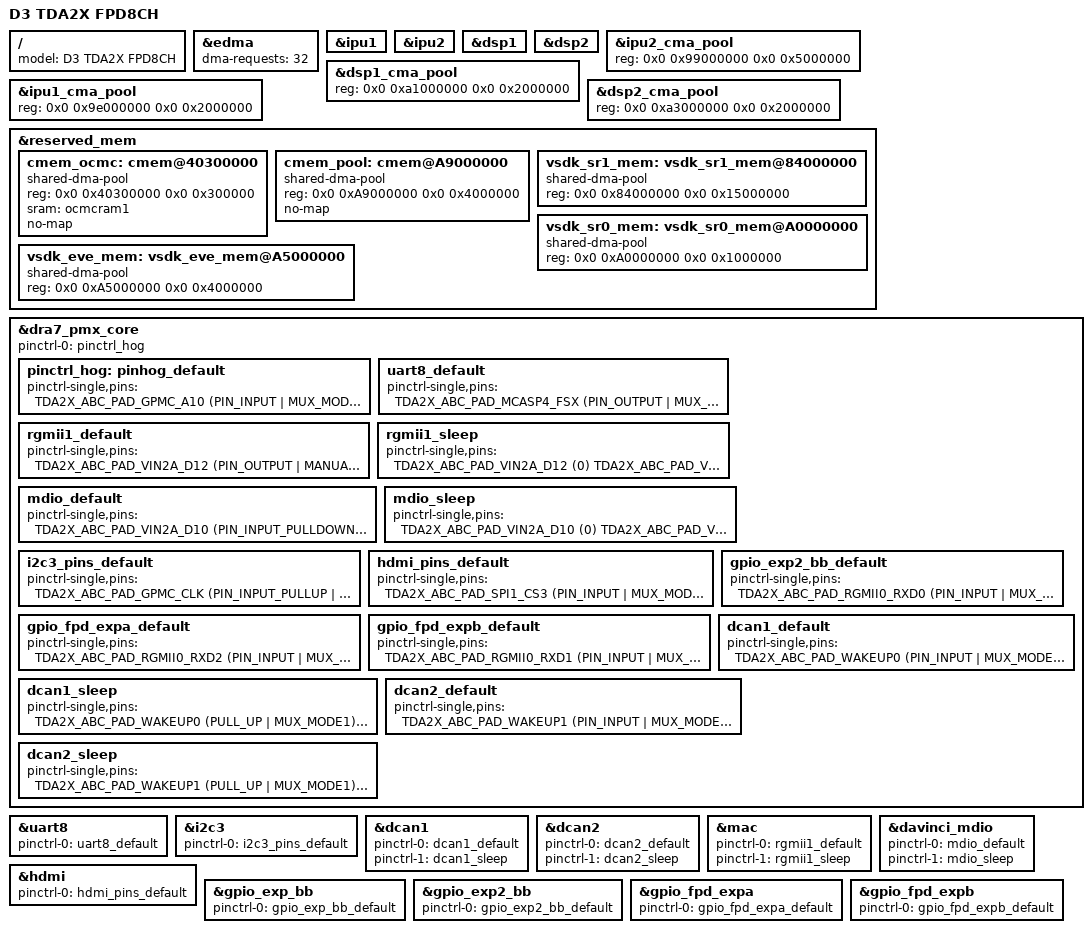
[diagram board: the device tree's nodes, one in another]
/*
 * Copyright (C) 2016 D3 Engineering
 *
 * Based on am571x-idk.dts
 * Copyright (C) 2015 Texas Instruments Incorporated
 *
 * This program is free software; you can redistribute it and/or modify
 * it under the terms of the GNU General Public License version 2 as
 * published by the Free Software Foundation.
 */
/dts-v1/;

#include "d3-tda2xx-tda2x.dtsi"
#include "d3-fpd8ch-baseboard.dtsi"
#include <dt-bindings/gpio/gpio.h>
#include <dt-bindings/interrupt-controller/irq.h>
#include <dt-bindings/net/ti-dp83867.h>

#define DISABLE_PRCM(label) &label { ti,no-idle; ti,no-reset-on-init; }
#define DISABLE_COMPLETE(label) &label { status = "disabled"; ti,no-idle; ti,no-reset-on-init; }
#define LATE_ATTACH(label) &label { ti,late-attach; ti,no-idle; ti,no-reset-on-init; }

/ {
	model = "D3 TDA2X FPD8CH";
};

/* modules used by BIOS, disable from Linux */
DISABLE_COMPLETE(vip1);
DISABLE_COMPLETE(vip2);
DISABLE_COMPLETE(vip3);
DISABLE_COMPLETE(i2c4);
DISABLE_COMPLETE(i2c5);
DISABLE_COMPLETE(wdt2);
DISABLE_COMPLETE(vpe);
DISABLE_COMPLETE(ocmcram1);
DISABLE_COMPLETE(hdmi);
DISABLE_COMPLETE(hdmi0);

/* modules shared between BIOS and Linux, Do not reset or cutoff clks */
DISABLE_PRCM(gpio1);
DISABLE_PRCM(gpio2);
DISABLE_PRCM(gpio3);
DISABLE_PRCM(gpio4);
DISABLE_PRCM(gpio5);
DISABLE_PRCM(gpio6);

/* Linux uses first 32 channels, BIOS uses last 32 */
&edma {
	dma-requests = <32>;
};

&ipu1 {
	/delete-property/ watchdog-timers;
};

&ipu2 {
	/delete-property/ watchdog-timers;
};

&dsp1 {
	/delete-property/ watchdog-timers;
};

&dsp2 {
	/delete-property/ watchdog-timers;
};

/* Update the CMA regions for Vision SDK binaries */
&ipu2_cma_pool {
	reg = <0x0 0x99000000 0x0 0x5000000>;
};

&dsp1_cma_pool {
	reg = <0x0 0xa1000000 0x0 0x2000000>;
};

&ipu1_cma_pool {
	reg = <0x0 0x9e000000 0x0 0x2000000>;
};

&dsp2_cma_pool {
	reg = <0x0 0xa3000000 0x0 0x2000000>;
};

/* Additional memory regions required for Vision SDK
 * Keep this in sync with VSDK apps/build/tda2xx/mem_segment_definition_linux.xs
 */
&reserved_mem {
	cmem_ocmc: cmem@40300000 {
		compatible = "shared-dma-pool";
		reg = <0x0 0x40300000 0x0 0x300000>;
		sram = <&ocmcram1>;
		no-map;
		status = "okay";
	};

	cmem_pool: cmem@A9000000 {
		compatible = "shared-dma-pool";
		reg = <0x0 0xA9000000 0x0 0x4000000>;
		no-map;
		status = "okay";
	};

	vsdk_sr1_mem: vsdk_sr1_mem@84000000 {
		compatible = "shared-dma-pool";
		reg = <0x0 0x84000000 0x0 0x15000000>;
		status = "okay";
	};

	vsdk_sr0_mem: vsdk_sr0_mem@A0000000 {
		compatible = "shared-dma-pool";
		reg = <0x0 0xA0000000 0x0 0x1000000>;
		status = "okay";
	};

	vsdk_eve_mem: vsdk_eve_mem@A5000000 {
		compatible = "shared-dma-pool";
		reg = <0x0 0xA5000000 0x0 0x4000000>;
		status = "okay";
	};
};

&dra7_pmx_core {
	pinctrl-names = "default";
	pinctrl-0 = <&pinctrl_hog>;

	pinctrl_hog: pinhog_default {
		pinctrl-single,pins = <
			TDA2X_ABC_PAD_GPMC_A10	(PIN_INPUT | MUX_MODE14) /* gpmc_a10.gpio2_0 */

			/* Isolated IO */
			TDA2X_ABC_PAD_GPMC_OEN_REN (PIN_INPUT | MUX_MODE14) /* gpmc_oen_ren.gpio2_24 */
			TDA2X_ABC_PAD_GPMC_WEN (PIN_INPUT | MUX_MODE14) /* gpmc_wen.gpio2_25 */
			TDA2X_ABC_PAD_GPMC_WAIT0 (PIN_OUTPUT | MUX_MODE14) /* gpmc_wait10.gpio2_28 */
			TDA2X_ABC_PAD_GPMC_CS0 (PIN_OUTPUT | MUX_MODE14) /* gpmc_cs0.gpio2_19 */

#if 0
			/* VIN1A pinmux */
			TDA2X_ABC_PAD_VIN1A_HSYNC0  (PIN_INPUT | MUX_MODE0) /* vin1a_hsync0.vin1a_hsync0 */
			TDA2X_ABC_PAD_VIN1A_VSYNC0  (PIN_INPUT | MUX_MODE0) /* vin1a_vsync0.vin1a_vsync0 */
			TDA2X_ABC_PAD_VIN1A_CLK0  (PIN_INPUT | MUX_MODE0) /* vin1a_clk0.vin1a_clk0 */
			TDA2X_ABC_PAD_VIN1A_D0  (PIN_INPUT | MUX_MODE0) /* vin1a_d0.vin1a_d0 */
			TDA2X_ABC_PAD_VIN1A_D1  (PIN_INPUT | MUX_MODE0) /* vin1a_d1.vin1a_d1 */
			TDA2X_ABC_PAD_VIN1A_D2  (PIN_INPUT | MUX_MODE0) /* vin1a_d2.vin1a_d2 */
			TDA2X_ABC_PAD_VIN1A_D3  (PIN_INPUT | MUX_MODE0) /* vin1a_d3.vin1a_d3 */
			TDA2X_ABC_PAD_VIN1A_D4  (PIN_INPUT | MUX_MODE0) /* vin1a_d4.vin1a_d4 */
			TDA2X_ABC_PAD_VIN1A_D5  (PIN_INPUT | MUX_MODE0) /* vin1a_d5.vin1a_d5 */
			TDA2X_ABC_PAD_VIN1A_D6  (PIN_INPUT | MUX_MODE0) /* vin1a_d6.vin1a_d6 */
			TDA2X_ABC_PAD_VIN1A_D7  (PIN_INPUT | MUX_MODE0) /* vin1a_d7.vin1a_d7 */
			TDA2X_ABC_PAD_VIN1A_D8  (PIN_INPUT | MUX_MODE0) /* vin1a_d8.vin1a_d8 */
			TDA2X_ABC_PAD_VIN1A_D9  (PIN_INPUT | MUX_MODE0) /* vin1a_d9.vin1a_d9 */
			TDA2X_ABC_PAD_VIN1A_D10  (PIN_INPUT | MUX_MODE0) /* vin1a_d10.vin1a_d10 */
			TDA2X_ABC_PAD_VIN1A_D11  (PIN_INPUT | MUX_MODE0) /* vin1a_d11.vin1a_d11 */

			/* VIN1B pinmux */
			TDA2X_ABC_PAD_VIN1A_DE0  (PIN_INPUT | MUX_MODE1) /* vin1a_de0.vin1b_hsync1 */
			TDA2X_ABC_PAD_VIN1A_FLD0  (PIN_INPUT | MUX_MODE1) /* vin1a_fld0.vin1b_vsync1 */
			TDA2X_ABC_PAD_VIN1B_CLK1 (PIN_INPUT | MUX_MODE0) /* vin1b_clk1.vin1b_clk1 */
			TDA2X_ABC_PAD_VIN1A_D23  (PIN_INPUT | MUX_MODE1) /* vin1a_d23.vin1b_d0 */
			TDA2X_ABC_PAD_VIN1A_D22  (PIN_INPUT | MUX_MODE1) /* vin1a_d22.vin1b_d1 */
			TDA2X_ABC_PAD_VIN1A_D21  (PIN_INPUT | MUX_MODE1) /* vin1a_d21.vin1b_d2 */
			TDA2X_ABC_PAD_VIN1A_D20  (PIN_INPUT | MUX_MODE1) /* vin1a_d20.vin1b_d3 */
			TDA2X_ABC_PAD_VIN1A_D19  (PIN_INPUT | MUX_MODE1) /* vin1a_d19.vin1b_d4 */
			TDA2X_ABC_PAD_VIN1A_D18  (PIN_INPUT | MUX_MODE1) /* vin1a_d18.vin1b_d5 */
			TDA2X_ABC_PAD_VIN1A_D17  (PIN_INPUT | MUX_MODE1) /* vin1a_d17.vin1b_d6 */
			TDA2X_ABC_PAD_VIN1A_D16  (PIN_INPUT | MUX_MODE1) /* vin1a_d16.vin1b_d7 */

			/* VIN2A pinmux */
			TDA2X_ABC_PAD_VIN2A_HSYNC0  (PIN_INPUT | MUX_MODE0) /* vin2a_hsync0.vin2a_hsync0 */
			TDA2X_ABC_PAD_VIN2A_VSYNC0  (PIN_INPUT | MUX_MODE0) /* vin2a_vsync0.vin2a_vsync0 */
			TDA2X_ABC_PAD_VIN2A_CLK0  (PIN_INPUT | MUX_MODE0) /* vin2a_clk0.vin2a_clk0 */
			TDA2X_ABC_PAD_VIN2A_D0  (PIN_INPUT | MUX_MODE0) /* vin2a_d0.vin2a_d0 */
			TDA2X_ABC_PAD_VIN2A_D1  (PIN_INPUT | MUX_MODE0) /* vin2a_d1.vin2a_d1 */
			TDA2X_ABC_PAD_VIN2A_D2  (PIN_INPUT | MUX_MODE0) /* vin2a_d2.vin2a_d2 */
			TDA2X_ABC_PAD_VIN2A_D3  (PIN_INPUT | MUX_MODE0) /* vin2a_d3.vin2a_d3 */
			TDA2X_ABC_PAD_VIN2A_D4  (PIN_INPUT | MUX_MODE0) /* vin2a_d4.vin2a_d4 */
			TDA2X_ABC_PAD_VIN2A_D5  (PIN_INPUT | MUX_MODE0) /* vin2a_d5.vin2a_d5 */
			TDA2X_ABC_PAD_VIN2A_D6  (PIN_INPUT | MUX_MODE0) /* vin2a_d6.vin2a_d6 */
			TDA2X_ABC_PAD_VIN2A_D7  (PIN_INPUT | MUX_MODE0) /* vin2a_d7.vin2a_d7 */
			TDA2X_ABC_PAD_VIN2A_D8  (PIN_INPUT | MUX_MODE0) /* vin2a_d8.vin2a_d8 */
			TDA2X_ABC_PAD_VIN2A_D9  (PIN_INPUT | MUX_MODE0) /* vin2a_d9.vin2a_d9 */

			/* VIN3A pinmux */
			TDA2X_ABC_PAD_GPMC_A8    (PIN_INPUT | MUX_MODE2) /* gpmc_cs3.vin3a_hsync0 */
			TDA2X_ABC_PAD_GPMC_A9    (PIN_INPUT | MUX_MODE2) /* gpmc_cs3.vin3a_vsync0 */
			TDA2X_ABC_PAD_GPMC_CS3   (PIN_INPUT | MUX_MODE2) /* gpmc_cs3.vin3a_clk0 */
			TDA2X_ABC_PAD_GPMC_AD0   (PIN_INPUT | MUX_MODE2) /* gpmc_ad0.vin3a_d0 */
			TDA2X_ABC_PAD_GPMC_AD1   (PIN_INPUT | MUX_MODE2) /* gpmc_ad1.vin3a_d1 */
			TDA2X_ABC_PAD_GPMC_AD2   (PIN_INPUT | MUX_MODE2) /* gpmc_ad2.vin3a_d2 */
			TDA2X_ABC_PAD_GPMC_AD3   (PIN_INPUT | MUX_MODE2) /* gpmc_ad3.vin3a_d3 */
			TDA2X_ABC_PAD_GPMC_AD4   (PIN_INPUT | MUX_MODE2) /* gpmc_ad4.vin3a_d4 */
			TDA2X_ABC_PAD_GPMC_AD5   (PIN_INPUT | MUX_MODE2) /* gpmc_ad5.vin3a_d5 */
			TDA2X_ABC_PAD_GPMC_AD6   (PIN_INPUT | MUX_MODE2) /* gpmc_ad6.vin3a_d6 */
			TDA2X_ABC_PAD_GPMC_AD7   (PIN_INPUT | MUX_MODE2) /* gpmc_ad7.vin3a_d7 */
			TDA2X_ABC_PAD_GPMC_AD8   (PIN_INPUT | MUX_MODE2) /* gpmc_ad8.vin3a_d8 */
			TDA2X_ABC_PAD_GPMC_AD9   (PIN_INPUT | MUX_MODE2) /* gpmc_ad9.vin3a_d9 */
			TDA2X_ABC_PAD_GPMC_AD10  (PIN_INPUT | MUX_MODE2) /* gpmc_ad10.vin3a_d10 */
			TDA2X_ABC_PAD_GPMC_AD11  (PIN_INPUT | MUX_MODE2) /* gpmc_ad11.vin3a_d11 */

			/* VIN4A pinmux*/
			TDA2X_ABC_PAD_GPIO6_14  (PIN_INPUT | MUX_MODE8) /* gpio6_14.vin4a_hsync0 */
			TDA2X_ABC_PAD_GPIO6_15  (PIN_INPUT | MUX_MODE8) /* gpio6_15.vin4a_vsync0 */
			TDA2X_ABC_PAD_XREF_CLK2  (PIN_INPUT | MUX_MODE8) /* xref_clk2.vin4a_clk0 */
			TDA2X_ABC_PAD_MCASP1_ACLKR  (PIN_INPUT | MUX_MODE8) /* mcasp1_aclkr.vin4a_d0 */
			TDA2X_ABC_PAD_MCASP1_FSR  (PIN_INPUT | MUX_MODE8) /* mcasp1_fsr.vin4a_d1 */
			TDA2X_ABC_PAD_MCASP1_AXR2  (PIN_INPUT | MUX_MODE8) /* mcasp1_axr2.vin4a_d2 */
			TDA2X_ABC_PAD_MCASP1_AXR3  (PIN_INPUT | MUX_MODE8) /* mcasp1_axr3.vin4a_d3 */
			TDA2X_ABC_PAD_MCASP1_AXR4  (PIN_INPUT | MUX_MODE8) /* mcasp1_axr4.vin4a_d4 */
			TDA2X_ABC_PAD_MCASP1_AXR5  (PIN_INPUT | MUX_MODE8) /* mcasp1_axr5.vin4a_d5 */
			TDA2X_ABC_PAD_MCASP1_AXR6  (PIN_INPUT | MUX_MODE8) /* mcasp1_axr6.vin4a_d6 */
			TDA2X_ABC_PAD_MCASP1_AXR7  (PIN_INPUT | MUX_MODE8) /* mcasp1_axr7.vin4a_d7 */
			TDA2X_ABC_PAD_MCASP2_ACLKR  (PIN_INPUT | MUX_MODE8) /* mcasp2_aclkr.vin4a_d8 */
			TDA2X_ABC_PAD_MCASP2_FSR  (PIN_INPUT | MUX_MODE8) /* mcasp2_fsr.vin4a_d9 */
			TDA2X_ABC_PAD_MCASP2_AXR0  (PIN_INPUT | MUX_MODE8) /* mcasp2_axr0.vin4a_d10 */
			TDA2X_ABC_PAD_MCASP2_AXR1  (PIN_INPUT | MUX_MODE8) /* mcasp2_fsr.vin4a_d11 */

			/* VIN4B pinmux */
			TDA2X_ABC_PAD_RGMII0_TXD2  (PIN_INPUT | MUX_MODE5) /* rgmii0_txd2.vin4b_hsync1 */
			TDA2X_ABC_PAD_RGMII0_TXD1  (PIN_INPUT | MUX_MODE5) /* rgmii0_txd1.vin4b_vsync1 */
			TDA2X_ABC_PAD_MDIO_MCLK  (PIN_INPUT | MUX_MODE5) /* mdio_mclk.vin4b_clk1 */
			TDA2X_ABC_PAD_MDIO_D  (PIN_INPUT | MUX_MODE5) /* mdio_d.vin4b_d0 */
			TDA2X_ABC_PAD_UART3_RXD  (PIN_INPUT | MUX_MODE5) /* uart3_rxd.vin4b_d1 */
			TDA2X_ABC_PAD_UART3_TXD  (PIN_INPUT | MUX_MODE5) /* uart3_rxd.vin4b_d2 */
			TDA2X_ABC_PAD_RGMII0_TXC  (PIN_INPUT | MUX_MODE5) /* rgmii0_txc.vin4b_d3 */
			TDA2X_ABC_PAD_RGMII0_TXCTL  (PIN_INPUT | MUX_MODE5) /* rgmii0_txctl.vin4b_d4 */
			TDA2X_ABC_PAD_RGMII0_RXC  (PIN_INPUT | MUX_MODE5) /* rgmii0_rxc.vin4b_d5 */
			TDA2X_ABC_PAD_RGMII0_RXCTL  (PIN_INPUT | MUX_MODE5) /* rgmii0_rxctl.vin4b_d6 */
			TDA2X_ABC_PAD_RGMII0_RXD3  (PIN_INPUT | MUX_MODE5) /* rgmii0_rxd3.vin4b_d7 */

			/* VIN5A pinmux */
			TDA2X_ABC_PAD_MMC3_DAT6  (PIN_INPUT | MUX_MODE9) /* mmc3_dat6.vin5a_hsync0 */
			TDA2X_ABC_PAD_MMC3_DAT7  (PIN_INPUT | MUX_MODE9) /* mmc3_dat7.vin5a_vsync0 */
			TDA2X_ABC_PAD_GPIO6_10  (PIN_INPUT | MUX_MODE9) /* gpio6_10.vin5a_clk0 */
			TDA2X_ABC_PAD_GPIO6_11  (PIN_INPUT | MUX_MODE9) /* gpio6_11.vin5a_de0 */
			TDA2X_ABC_PAD_MCASP3_AXR1  (PIN_INPUT | MUX_MODE9) /* mcasp3_axr1.vin5a_fld0 */
			TDA2X_ABC_PAD_MMC3_DAT5  (PIN_INPUT | MUX_MODE9) /* mmc3_dat5.vin5a_d0 */
			TDA2X_ABC_PAD_MMC3_DAT4  (PIN_INPUT | MUX_MODE9) /* mmc3_dat4.vin5a_d1 */
			TDA2X_ABC_PAD_MMC3_DAT3  (PIN_INPUT | MUX_MODE9) /* mmc3_dat3.vin5a_d2 */
			TDA2X_ABC_PAD_MMC3_DAT2  (PIN_INPUT | MUX_MODE9) /* mmc3_dat2.vin5a_d3 */
			TDA2X_ABC_PAD_MMC3_DAT1  (PIN_INPUT | MUX_MODE9) /* mmc3_dat1.vin5a_d4 */
			TDA2X_ABC_PAD_MMC3_DAT0  (PIN_INPUT | MUX_MODE9) /* mmc3_dat0.vin5a_d5 */
			TDA2X_ABC_PAD_MMC3_CMD  (PIN_INPUT | MUX_MODE9) /* mmc3_dat5.vin5a_d6 */
			TDA2X_ABC_PAD_MMC3_CLK  (PIN_INPUT | MUX_MODE9) /* mmc3_dat5.vin5a_d7 */
			TDA2X_ABC_PAD_MCASP5_AXR1  (PIN_INPUT | MUX_MODE9) /* mcasp5_axr1.vin5a_d8 */
			TDA2X_ABC_PAD_MCASP5_AXR0  (PIN_INPUT | MUX_MODE9) /* mcasp5_axr0.vin5a_d9 */
			TDA2X_ABC_PAD_MCASP5_FSX  (PIN_INPUT | MUX_MODE9) /* mcasp5_fsx.vin5a_d10 */
			TDA2X_ABC_PAD_MCASP5_ACLKX  (PIN_INPUT | MUX_MODE9) /* mcasp5_aclkx.vin5a_d11 */

			/* VIN6A pinmux */
			TDA2X_ABC_PAD_MCASP1_AXR1  (PIN_INPUT | MUX_MODE7) /* mcasp1_axr1.vin6a_hsync0 */
			TDA2X_ABC_PAD_MCASP1_AXR0  (PIN_INPUT | MUX_MODE7) /* mcasp1_axr0.vin6a_vsync0 */
			TDA2X_ABC_PAD_XREF_CLK1  (PIN_INPUT | MUX_MODE7) /* xref_clk1.vin6a_clk0 */
			TDA2X_ABC_PAD_XREF_CLK0  (PIN_INPUT | MUX_MODE7) /* xref_clk0.vin6a_d0 */
			TDA2X_ABC_PAD_MCASP3_AXR0  (PIN_INPUT | MUX_MODE7) /* mcasp3_axr0.vin6a_d1 */
			TDA2X_ABC_PAD_MCASP3_FSX  (PIN_INPUT | MUX_MODE7) /* mcasp3_fsx.vin6a_d2 */
			TDA2X_ABC_PAD_MCASP3_ACLKX  (PIN_INPUT | MUX_MODE7) /* mcasp3_aclkx.vin6a_d3 */
			TDA2X_ABC_PAD_MCASP2_AXR3  (PIN_INPUT | MUX_MODE7) /* mcasp3_axr3.vin6a_d4 */
			TDA2X_ABC_PAD_MCASP2_AXR2  (PIN_INPUT | MUX_MODE7) /* mcasp3_axr2.vin6a_d5 */
			TDA2X_ABC_PAD_MCASP2_FSX  (PIN_INPUT | MUX_MODE7) /* mcasp2_fsx.vin6a_d6 */
			TDA2X_ABC_PAD_MCASP2_ACLKX  (PIN_INPUT | MUX_MODE7) /* mcasp2_aclkx.vin6a_d7 */
			TDA2X_ABC_PAD_MCASP1_AXR15  (PIN_INPUT | MUX_MODE7) /* mcasp1_axr15.vin6a_d8 */
			TDA2X_ABC_PAD_MCASP1_AXR14  (PIN_INPUT | MUX_MODE7) /* mcasp1_axr14.vin6a_d9 */
			TDA2X_ABC_PAD_MCASP1_AXR13  (PIN_INPUT | MUX_MODE7) /* mcasp1_axr13.vin6a_d10 */

			/*TDA2X_ABC_PAD_MCASP1_AXR12  (PIN_INPUT | MUX_MODE7) *//* mcasp1_axr12.vin6a_d11 */
#endif

			/*Ultrasonic*/
			TDA2X_ABC_PAD_GPMC_BEN0 (PIN_OUTPUT | MUX_MODE14) /* gpmc_ben0.gpio2_26 */
			TDA2X_ABC_PAD_MCASP1_AXR12 (PIN_OUTPUT | MUX_MODE14) /* mcasp1_axr12.gpio4_18 */
			TDA2X_ABC_PAD_GPMC_A11 (PIN_OUTPUT | MUX_MODE14) /* gpmc_a11.gpio2_1 */
			TDA2X_ABC_PAD_GPMC_BEN1 (PIN_OUTPUT | MUX_MODE14) /* gpmc_ben1.gpio2_27 */
			TDA2X_ABC_PAD_SPI1_D1 (PIN_OUTPUT | MUX_MODE14) /* spi2_d1.gpio7_8 */
			TDA2X_ABC_PAD_SPI1_D0 (PIN_OUTPUT | MUX_MODE14) /* spi1_d0.gpio7_9 */
			TDA2X_ABC_PAD_SPI1_CS1 (PIN_OUTPUT | MUX_MODE14) /* spi1_cs1.gpio7_11 */
			TDA2X_ABC_PAD_SPI1_CS0 (PIN_OUTPUT | MUX_MODE14) /* spi1_cs0.gpio7_10 */
			TDA2X_ABC_PAD_SPI1_SCLK (PIN_OUTPUT | MUX_MODE14) /* spi1_sclk.gpio7_7 */
		>;
	};

	uart8_default: uart8_default {
		pinctrl-single,pins = <
			TDA2X_ABC_PAD_MCASP4_FSX (PIN_OUTPUT | MUX_MODE3) /* mcasp4_fsx.uart8_txd */
			TDA2X_ABC_PAD_MCASP4_ACLKX (PIN_INPUT | MUX_MODE3) /* mcasp4_aclkx.uart8_rxd */
		>;
	};

	rgmii1_default: rgmii1_default {
		pinctrl-single,pins = <
			TDA2X_ABC_PAD_VIN2A_D12	(PIN_OUTPUT | MANUAL_MODE | MUX_MODE3) /* vin2a_d12.rgmii1_txc */
			TDA2X_ABC_PAD_VIN2A_D13	(PIN_OUTPUT | MANUAL_MODE | MUX_MODE3) /* vin2a_d13.rgmii1_txctl */
			TDA2X_ABC_PAD_VIN2A_D14	(PIN_OUTPUT | MANUAL_MODE | MUX_MODE3) /* vin2a_d14.rgmii1_txd3 */
			TDA2X_ABC_PAD_VIN2A_D15	(PIN_OUTPUT | MANUAL_MODE | MUX_MODE3) /* vin2a_d15.rgmii1_txd2 */
			TDA2X_ABC_PAD_VIN2A_D16	(PIN_OUTPUT | MANUAL_MODE | MUX_MODE3) /* vin2a_d16.rgmii1_txd1 */
			TDA2X_ABC_PAD_VIN2A_D17	(PIN_OUTPUT | MANUAL_MODE | MUX_MODE3) /* vin2a_d17.rgmii1_txd0 */
			TDA2X_ABC_PAD_VIN2A_D18	(PIN_INPUT_PULLDOWN | MANUAL_MODE | MUX_MODE3) /* vin2a_d18.rgmii1_rxc */
			TDA2X_ABC_PAD_VIN2A_D19	(PIN_INPUT_PULLDOWN | MANUAL_MODE | MUX_MODE3) /* vin2a_d19.rgmii1_rxctl */
			TDA2X_ABC_PAD_VIN2A_D20	(PIN_INPUT_PULLDOWN | MANUAL_MODE | MUX_MODE3) /* vin2a_d20.rgmii1_rxd3 */
			TDA2X_ABC_PAD_VIN2A_D21	(PIN_INPUT_PULLDOWN | MANUAL_MODE | MUX_MODE3) /* vin2a_d21.rgmii1_rxd2 */
			TDA2X_ABC_PAD_VIN2A_D22	(PIN_INPUT_PULLDOWN | MANUAL_MODE | MUX_MODE3) /* vin2a_d22.rgmii1_rxd1 */
			TDA2X_ABC_PAD_VIN2A_D23	(PIN_INPUT_PULLDOWN | MANUAL_MODE | MUX_MODE3) /* vin2a_d23.rgmii1_rxd0 */
		>;

	};

	rgmii1_sleep: rgmii1_sleep {
		pinctrl-single,pins = <
			TDA2X_ABC_PAD_VIN2A_D12	(0) /* vin2a_d12.rgmii1_txc */
			TDA2X_ABC_PAD_VIN2A_D13	(0) /* vin2a_d13.rgmii1_txctl */
			TDA2X_ABC_PAD_VIN2A_D14	(0) /* vin2a_d14.rgmii1_txd3 */
			TDA2X_ABC_PAD_VIN2A_D15	(0) /* vin2a_d15.rgmii1_txd2 */
			TDA2X_ABC_PAD_VIN2A_D16	(0) /* vin2a_d16.rgmii1_txd1 */
			TDA2X_ABC_PAD_VIN2A_D17	(0) /* vin2a_d17.rgmii1_txd0 */
			TDA2X_ABC_PAD_VIN2A_D18	(0) /* vin2a_d18.rgmii1_rxc */
			TDA2X_ABC_PAD_VIN2A_D19	(0) /* vin2a_d19.rgmii1_rxctl */
			TDA2X_ABC_PAD_VIN2A_D20	(0) /* vin2a_d20.rgmii1_rxd3 */
			TDA2X_ABC_PAD_VIN2A_D21	(0) /* vin2a_d21.rgmii1_rxd2 */
			TDA2X_ABC_PAD_VIN2A_D22	(0) /* vin2a_d22.rgmii1_rxd1 */
			TDA2X_ABC_PAD_VIN2A_D23	(0) /* vin2a_d23.rgmii1_rxd0 */
		>;

	};

	mdio_default: mdio_default {
		pinctrl-single,pins = <
			/* MDIO */
			TDA2X_ABC_PAD_VIN2A_D10	(PIN_INPUT_PULLDOWN | MUX_MODE3) /* vin2a_d10.mdio_mclk */
			TDA2X_ABC_PAD_VIN2A_D11	(PIN_INPUT_PULLDOWN | MUX_MODE3) /* vin2a_d11.mdio_d */
		>;
	};

	mdio_sleep: mdio_sleep {
		pinctrl-single,pins = <
			TDA2X_ABC_PAD_VIN2A_D10	(0) /* vin2a_d10.mdio_mclk */
			TDA2X_ABC_PAD_VIN2A_D11	(0) /* vin2a_d11.mdio_d */
		>;
	};

	i2c3_pins_default: i2c3_pins_default {
		pinctrl-single,pins = <
			TDA2X_ABC_PAD_GPMC_CLK	(PIN_INPUT_PULLUP | MUX_MODE8) /* gpmc_clk.i2c3_scl */
			TDA2X_ABC_PAD_GPMC_ADVN_ALE	(PIN_INPUT_PULLUP | MUX_MODE8) /* gpmc_advn_ale.i2c3_sda */
		>;
	};

#if 0
	i2c4_pins_default: i2c4_pins_default {
		pinctrl-single,pins = <
			TDA2X_ABC_PAD_GPMC_A0	(PIN_INPUT_PULLUP | MUX_MODE7) /* gpmc_a0.i2c4_scl */
			TDA2X_ABC_PAD_GPMC_A1	(PIN_INPUT_PULLUP | MUX_MODE7) /* gpmc_a1.i2c4_sda */
		>;
	};

	i2c5_pins_default: i2c5_pins_default {
		pinctrl-single,pins = <
			TDA2X_ABC_PAD_GPMC_A4	(PIN_INPUT_PULLUP | MUX_MODE7) /* gpmc_a4.i2c5_scl */
			TDA2X_ABC_PAD_GPMC_A5	(PIN_INPUT_PULLUP | MUX_MODE7) /* gpmc_a5.i2c5_sda */
		>;
	};
#endif

	hdmi_pins_default: hdmi_pins_default {
		pinctrl-single,pins = <
			TDA2X_ABC_PAD_SPI1_CS3 (PIN_INPUT | MUX_MODE6) /* spi1_cs3.hdmi1_cec */
			TDA2X_ABC_PAD_I2C2_SDA (PIN_INPUT | MUX_MODE1) /* i2c2_sda.hdmi1_ddc_scl */
			TDA2X_ABC_PAD_I2C2_SCL (PIN_INPUT | MUX_MODE1) /* i2c2_scl.hdmi1_ddc_sda */
		>;
	};

	gpio_exp2_bb_default: gpio_exp2_bb_default {
		pinctrl-single,pins = <
			TDA2X_ABC_PAD_RGMII0_RXD0 (PIN_INPUT | MUX_MODE11)	/* rgmii0_rxd0.gpio5_31 */
		>;
	};

	gpio_fpd_expa_default: gpio_fpd_expa_default {
		pinctrl-single,pins = <
			TDA2X_ABC_PAD_RGMII0_RXD2 (PIN_INPUT | MUX_MODE11)	/* rgmii0_rxd2.gpio5_29 */
		>;
	};

	gpio_fpd_expb_default: gpio_fpd_expb_default {
		pinctrl-single,pins = <
			TDA2X_ABC_PAD_RGMII0_RXD1 (PIN_INPUT | MUX_MODE11)	/* rgmii0_rxd1.gpio5_30 */
		>;
	};

	dcan1_default: dcan1_default {
		pinctrl-single,pins = <
			TDA2X_ABC_PAD_WAKEUP0 (PIN_INPUT | MUX_MODE1)		/* wakeup0.dcan1_rx */
			TDA2X_ABC_PAD_DCAN1_TX (PIN_OUTPUT | MUX_MODE0)		/* dcan1_tx.dcan1_tx */
		>;
	};

	dcan1_sleep: dcan1_sleep {
		pinctrl-single,pins = <
			TDA2X_ABC_PAD_WAKEUP0 (PULL_UP | MUX_MODE1)		/* wakeup0.off */
			TDA2X_ABC_PAD_DCAN1_TX (PULL_UP | MUX_MODE0)		/* dcan1_tx.off */
		>;
	};

	dcan2_default: dcan2_default {
		pinctrl-single,pins = <
			TDA2X_ABC_PAD_WAKEUP1 (PIN_INPUT | MUX_MODE1)		/* wakeup1.dcan2_rx */
			TDA2X_ABC_PAD_SPI1_CS2 (PIN_OUTPUT | MUX_MODE4)		/* spi1_cs2.dcan2_tx */
		>;
	};

	dcan2_sleep: dcan2_sleep {
		pinctrl-single,pins = <
			TDA2X_ABC_PAD_WAKEUP1 (PULL_UP | MUX_MODE1)		/* wakeup1.off */
			TDA2X_ABC_PAD_SPI1_CS2 (PULL_UP | MUX_MODE4)		/* spi1_cs2.off */
		>;
	};
};


&uart8 {
	status = "okay";
	pinctrl-names = "default";
	pinctrl-0 = <&uart8_default>;
};


&i2c3 {
	pinctrl-names = "default";
	pinctrl-0 = <&i2c3_pins_default>;
};

#if 0
&i2c4 {
	pinctrl-names = "default";
	pinctrl-0 = <&i2c4_pins_default>;
};

&i2c5 {
	pinctrl-names = "default";
	pinctrl-0 = <&i2c5_pins_default>;
};
#endif

&dcan1 {
	pinctrl-names = "default", "sleep";
	pinctrl-0 = <&dcan1_default>;
	pinctrl-1 = <&dcan1_sleep>;
};

&dcan2 {
	pinctrl-names = "default", "sleep";
	pinctrl-0 = <&dcan2_default>;
	pinctrl-1 = <&dcan2_sleep>;
};

&mac {
	pinctrl-names = "default", "sleep";
	pinctrl-0 = <&rgmii1_default>;
	pinctrl-1 = <&rgmii1_sleep>;
};


&davinci_mdio {
	pinctrl-names = "default", "sleep";
	pinctrl-0 = <&mdio_default>;
	pinctrl-1 = <&mdio_sleep>;
};

&hdmi {
	pinctrl-names = "default";
	pinctrl-0 = <&hdmi_pins_default>;
};

&gpio_exp_bb {
	pinctrl-names = "default";
	pinctrl-0 = <&gpio_exp_bb_default>;
	/* interrupt-parent = <&gpio7>; */
	/* interrupts = <17 IRQ_TYPE_LEVEL_LOW>; */
};

&gpio_exp2_bb {
	pinctrl-names = "default";
	pinctrl-0 = <&gpio_exp2_bb_default>;
	/* interrupt-parent = <&gpio5>; */
	/* interrupts = <31 IRQ_TYPE_LEVEL_LOW>; */
};

&gpio_fpd_expa {
	pinctrl-names = "default";
	pinctrl-0 = <&gpio_fpd_expa_default>;
	/* interrupt-parent = <&gpio5>; */
	/* interrupts = <29 IRQ_TYPE_LEVEL_LOW>; */
};

&gpio_fpd_expb {
	pinctrl-names = "default";
	pinctrl-0 = <&gpio_fpd_expb_default>;
	/* interrupt-parent = <&gpio5>; */
	/* interrupts = <30 IRQ_TYPE_LEVEL_LOW>; */
};
